# STM32L4P5 register map
File version: 1.8
CPU: CM4 r0p1, little endian, MPU, FPU, 4 interrupt priority bits
Registers are 32-bit, read-write, reset 0x0 unless marked. A register's access mark holds for its fields unless they carry their own. Offsets are from the block's base; [hi:lo] are bit positions; lines under a group give offsets from that group; {n}, {i} and the like mark numbered series; 'fields as' and 'values as' point back to an identical list.

## OTG_FS_DEVICE — USB on the go full speed
Base 0x50000800
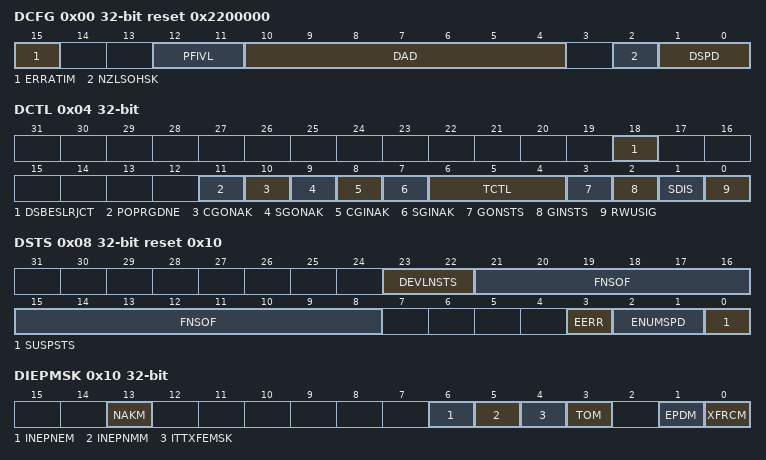
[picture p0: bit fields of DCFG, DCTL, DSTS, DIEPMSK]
0x00 DCFG reset 0x2200000 — OTG_FS device configuration register (OTG_FS_DCFG)
  [15] ERRATIM — Erratic error interrupt mask
  [12:11] PFIVL — Periodic frame interval
  [10:4] DAD — Device address
  [2] NZLSOHSK — Non-zero-length status OUT handshake
  [1:0] DSPD — Device speed
0x04 DCTL access per field — OTG_FS device control register (OTG_FS_DCTL)
  [18] DSBESLRJCT rw — Deep sleep BESL reject
  [11] POPRGDNE rw — Power-on programming done
  [10] CGONAK rw — Clear global OUT NAK
  [9] SGONAK rw — Set global OUT NAK
  [8] CGINAK rw — Clear global IN NAK
  [7] SGINAK rw — Set global IN NAK
  [6:4] TCTL rw — Test control
  [3] GONSTS ro — Global OUT NAK status
  [2] GINSTS ro — Global IN NAK status
  [1] SDIS rw — Soft disconnect
  [0] RWUSIG rw — Remote wakeup signaling
0x08 DSTS ro reset 0x10 — OTG_FS device status register (OTG_FS_DSTS)
  [23:22] DEVLNSTS — Device line status
  [21:8] FNSOF — Frame number of the received SOF
  [3] EERR — Erratic error
  [2:1] ENUMSPD — Enumerated speed
  [0] SUSPSTS — Suspend status
0x10 DIEPMSK — OTG_FS device IN endpoint common interrupt mask register (OTG_FS_DIEPMSK)
  [13] NAKM — NAK interrupt mask
  [6] INEPNEM — IN endpoint NAK effective mask
  [5] INEPNMM — IN token received with EP mismatch mask
  [4] ITTXFEMSK — IN token received when TxFIFO empty mask
  [3] TOM — Timeout condition mask (Non-isochronous endpoints)
  [1] EPDM — Endpoint disabled interrupt mask
  [0] XFRCM — Transfer completed interrupt mask
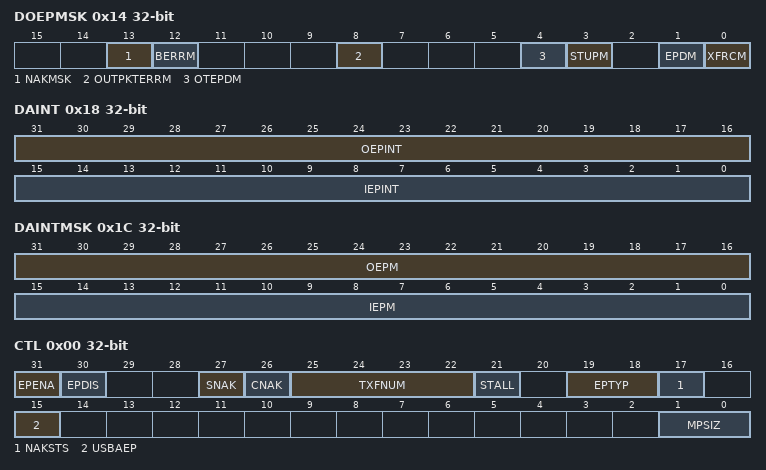
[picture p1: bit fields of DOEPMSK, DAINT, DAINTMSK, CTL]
0x14 DOEPMSK — OTG_FS device OUT endpoint common interrupt mask register (OTG_FS_DOEPMSK)
  [13] NAKMSK — NAK interrupt mask
  [12] BERRM — Babble error interrupt mask
  [8] OUTPKTERRM — Out packet error mask
  [4] OTEPDM — OUT token received when endpoint disabled mask
  [3] STUPM — SETUP phase done mask
  [1] EPDM — Endpoint disabled interrupt mask
  [0] XFRCM — Transfer completed interrupt mask
0x18 DAINT ro — OTG_FS device all endpoints interrupt register (OTG_FS_DAINT)
  [31:16] OEPINT — OUT endpoint interrupt bits
  [15:0] IEPINT — IN endpoint interrupt bits
0x1C DAINTMSK — OTG_FS all endpoints interrupt mask register (OTG_FS_DAINTMSK)
  [31:16] OEPM — OUT EP interrupt mask bits
  [15:0] IEPM — IN EP interrupt mask bits
0x28 DVBUSDIS reset 0x17D7 — OTG_FS device VBUS discharge time register
  [15:0] VBUSDT — Device VBUS discharge time
0x2C DVBUSPULSE reset 0x5B8 — OTG_FS device VBUS pulsing time register
  [11:0] DVBUSP — Device VBUS pulsing time
0x34 DIEPEMPMSK — OTG_FS device IN endpoint FIFO empty interrupt mask register
  [15:0] INEPTXFEM — IN EP Tx FIFO empty interrupt mask bits
0x100 DIEP0 group — Device IN endpoint 0
  0x00 CTL access per field — OTG_FS device control IN endpoint 0 control register (OTG_FS_DIEPCTL0)
    [31] EPENA rw — Endpoint enable
    [30] EPDIS ro — Endpoint disable
    [27] SNAK wo — Set NAK
    [26] CNAK wo — Clear NAK
    [25:22] TXFNUM rw — TxFIFO number
    [21] STALL rw — STALL handshake
    [19:18] EPTYP ro — Endpoint type
    [17] NAKSTS ro — NAK status
    [15] USBAEP ro — USB active endpoint
    [1:0] MPSIZ rw — Maximum packet size
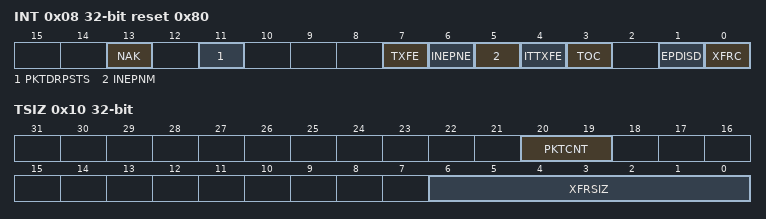
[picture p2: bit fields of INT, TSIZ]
  0x08 INT access per field reset 0x80 — device endpoint-x interrupt register
    [13] NAK rw — NAK input
    [11] PKTDRPSTS rw — Packet dropped status
    [7] TXFE ro
    [6] INEPNE rw
    [5] INEPNM rw — IN token received with EP mismatch
    [4] ITTXFE rw
    [3] TOC rw
    [1] EPDISD rw
    [0] XFRC rw
  0x10 TSIZ — device endpoint-0 transfer size register
    [20:19] PKTCNT — Packet count
    [6:0] XFRSIZ — Transfer size
  0x18 TXFSTS ro — OTG_FS device IN endpoint transmit FIFO status register
    [15:0] INEPTFSAV — IN endpoint TxFIFO space available
{0x100+0x20*i} DIEP{i} (i=1..5) group — Device IN endpoint X
  0x00 CTL access per field — OTG device endpoint-1 control register
    [31] EPENA rw
    [30] EPDIS rw
    [29] SODDFRM_SD1PID wo
    [28] SD0PID_SEVNFRM wo
    [27] SNAK wo
    [26] CNAK wo
    [25:22] TXFNUM rw
    [21] STALL rw — STALL handshake
    [19:18] EPTYP rw
    [17] NAKSTS ro
    [16] EONUM_DPID ro
    [15] USBAEP rw
    [10:0] MPSIZ rw
  0x08 INT access per field reset 0x80 — device endpoint-1 interrupt register
    fields as DIEP0.INT
  0x10 TSIZ — device endpoint-1 transfer size register
    [30:29] MCNT — Multi count
    [28:19] PKTCNT — Packet count
    [18:0] XFRSIZ — Transfer size
  0x18 TXFSTS ro — OTG_FS device IN endpoint transmit FIFO status register
    [15:0] INEPTFSAV — IN endpoint TxFIFO space available
0x300 DOEP0 group — Device OUT endpoint 0
  0x00 CTL access per field reset 0x8000 — device endpoint-0 control register
    [31] EPENA rw
    [30] EPDIS ro
    [27] SNAK wo
    [26] CNAK wo
    [21] STALL rw — STALL handshake
    [20] SNPM rw
    [19:18] EPTYP ro
    [17] NAKSTS ro
    [15] USBAEP ro
    [1:0] MPSIZ ro
  0x08 INT reset 0x80 — device endpoint-0 interrupt register
    [13] NAK — NAK input
    [12] BERR — Babble error interrupt
    [5] STSPHSRX — Status phase received for control write
    [4] OTEPDIS
    [3] STUP
    [1] EPDISD
    [0] XFRC
  0x10 TSIZ — device OUT endpoint-0 transfer size register
    [30:29] STUPCNT — SETUP packet count
    [19] PKTCNT — Packet count
    [6:0] XFRSIZ — Transfer size
{0x300+0x20*i} DOEP{i} (i=1..5) group — Device IN endpoint X
  0x00 CTL access per field — device endpoint-1 control register
    [31] EPENA rw
    [30] EPDIS rw
    [29] SODDFRM wo
    [28] SD0PID_SEVNFRM wo
    [27] SNAK wo
    [26] CNAK wo
    [21] STALL rw — STALL handshake
    [20] SNPM rw
    [19:18] EPTYP rw
    [17] NAKSTS ro
    [16] EONUM_DPID ro
    [15] USBAEP rw
    [10:0] MPSIZ rw
  0x08 INT reset 0x80 — device endpoint-1 interrupt register
    fields as DOEP0.INT
  0x10 TSIZ — device OUT endpoint-1 transfer size register
    [30:29] RXDPID_STUPCNT — Received data PID/SETUP packet count
    [28:19] PKTCNT — Packet count
    [18:0] XFRSIZ — Transfer size
